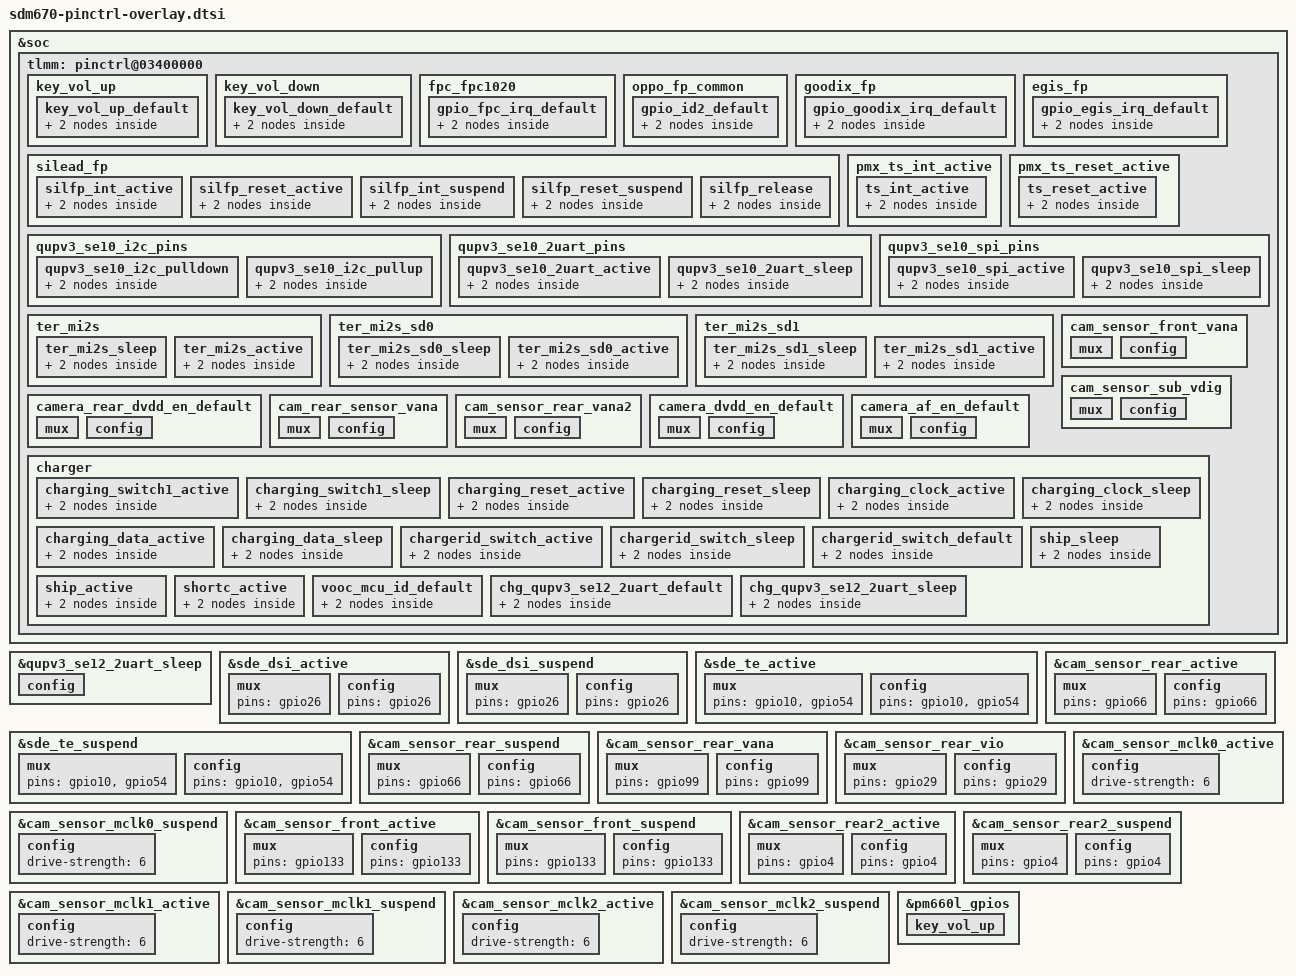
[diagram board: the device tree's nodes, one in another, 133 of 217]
&soc {
	tlmm: pinctrl@03400000 {
        key_vol_up {
            key_vol_up_default: key_vol_up_default {
                mux {
                    pins = "gpio24";
                    functions = "gpio";
                };

                config {
                    pins = "gpio24";
                    drive-strength = <2>;
                    bias-disable;
                    input-enable;
                };
            };
        };

        key_vol_down {
            key_vol_down_default: key_vol_down_default {
                mux {
                    pins = "gpio92";
                    functions = "gpio";
                };

                config {
                    pins = "gpio92";
                    drive-strength = <2>;
                    bias-disable;
                    input-enable;
                };
            };
        };

        fpc_fpc1020{
            gpio_fpc_irq_default: gpio_fpc_irq_default {
                mux {
                    pins = "gpio121";
                    function = "gpio";
                };
                config {
                    pins = "gpio121";
                    drive-strength = <2>;
                    bias-pull-up;
                    input-enable;
                };
            };
        };
    
        oppo_fp_common{
            gpio_id2_default: gpio_id2_default {
                mux {
                    pins = "gpio23";
                    function = "gpio";
                };
                config {
                    pins = "gpio23";
                    drive-strength = <2>;
                    bias-pull-up;
                    input-enable;
                };
            };
        };
    
        goodix_fp{
            gpio_goodix_irq_default: gpio_goodix_irq_default {
                mux {
                    pins = "gpio121";
                    function = "gpio";
                };
                config {
                    pins = "gpio121";
                    drive-strength = <2>;
                    bias-disable;
                    input-enable;
                };
            };
        };
    
        egis_fp{
            gpio_egis_irq_default: gpio_egis_irq_default {
                mux {
                    pins = "gpio121";
                    function = "gpio";
                };
                config {
                    pins = "gpio121";
                    drive-strength = <2>;
                    bias-disable;
                    input-enable;
                };
            };
        };
    
        silead_fp{
            silfp_int_active: silfp_int_active {
                            mux {
                                pins = "gpio121";
                                function = "gpio";
                            };
                            config {
                                pins = "gpio121";
                                drive-strength = <2>;
                                bias-disable;
                                input-enable;
                            };
            };
    
            silfp_reset_active: silfp_reset_active {
                            mux {
                                pins = "gpio80";
                                function = "gpio";
                            };
                            config {
                                pins = "gpio80";
                                drive-strength = <2>;
                                bias-disable;
                                output-low;
                            };
            };
    
            silfp_int_suspend: silfp_int_suspend {
                            mux {
                                pins = "gpio121";
                                function = "gpio";
                            };
                            config {
                                pins = "gpio121";
                                drive-strength = <2>;
                                bias-disable;
                                input-enable;
                            };
            };
    
            silfp_reset_suspend: silfp_reset_suspend {
                            mux {
                                pins = "gpio80";
                                function = "gpio";
                            };
                            config {
                                pins = "gpio80";
                                drive-strength = <2>;
                                bias-disable;
                                output-low;
                            };
            };
            silfp_release: silfp_release {
                            mux {
                                pins = "gpio121","gpio80";
                                function = "gpio";
                            };
                            config {
                                pins = "gpio121","gpio80";
                                drive-strength = <2>;
                                bias-disable;
                                output-low;
                            };
            };
        };

        pmx_ts_int_active {
            ts_int_active: ts_int_active {
                mux {
                    pins = "gpio125";
                    function = "gpio";
                };

                config {
                    pins = "gpio125";
                    drive-strength = <8>;
                    bias-pull-up;
                };
            };
        };

        pmx_ts_reset_active {
            ts_reset_active: ts_reset_active {
                mux {
                    pins = "gpio119";
                    function = "gpio";
                };

                config {
                    pins = "gpio119";
                    drive-strength = <8>;
                    bias-disable;
                };
            };
        };

        /delete-node/ qupv3_se4_spi_pins;


        qupv3_se10_i2c_pins: qupv3_se10_i2c_pins {
            qupv3_se10_i2c_pulldown: qupv3_se10_i2c_pulldown {
                mux {
                    pins = "gpio55", "gpio56";
                    function = "gpio";
                };

                config {
                    pins = "gpio55", "gpio56";
                    drive-strength = <2>;
                    bias-pull-down;
                    output-low;
                };
            };

            qupv3_se10_i2c_pullup: qupv3_se10_i2c_pullup {
                mux {
                    pins = "gpio55", "gpio56";
                    function = "gpio";
                };

                config {
                    pins = "gpio55", "gpio56";
                    drive-strength = <2>;
                    bias-pull-up;
                    input-enable;
                };
            };
        };

        qupv3_se10_2uart_pins: qupv3_se10_2uart_pins {
            qupv3_se10_2uart_active: qupv3_se10_2uart_active {
                mux {
                    pins = "gpio53";
                };

                config {
                    pins = "gpio53";
                };
            };

            qupv3_se10_2uart_sleep: qupv3_se10_2uart_sleep {
                mux {
                    pins = "gpio53";
                };

                config {
                    pins = "gpio53";
                };
            };
        };

        qupv3_se10_spi_pins: qupv3_se10_spi_pins {
            qupv3_se10_spi_active: qupv3_se10_spi_active {
                mux {
                    pins = "gpio53", "gpio55",
                                "gpio56";
                };

                config {
                    pins = "gpio53", "gpio55",
                                "gpio56";
                };
            };

            qupv3_se10_spi_sleep: qupv3_se10_spi_sleep {
                mux {
                    pins = "gpio53", "gpio55",
                                "gpio56";
                };

                config {
                    pins = "gpio53", "gpio55",
                                "gpio56";
                };
            };
        };

        /delete-node/ wcd_usbc_analog_en1;

        ter_mi2s {
            ter_mi2s_sleep: ter_mi2s_sleep {
                mux {
                    pins = "gpio75", "gpio76";
                    function = "ter_mi2s";
                };

                config {
                    pins = "gpio75", "gpio76";
                    drive-strength = <2>;   /* 2 mA */
                    bias-pull-down;
                    output-low;
                };
            };

            ter_mi2s_active: ter_mi2s_active {
                mux {
                    pins = "gpio75", "gpio76";
                    function = "ter_mi2s";
                };

                config {
                    pins = "gpio75", "gpio76";
                    drive-strength = <8>;   /* 8 mA */
                    output-high;
                };
            };
        };

        ter_mi2s_sd0 {
            ter_mi2s_sd0_sleep: ter_mi2s_sd0_sleep {
                mux {
                    pins = "gpio77";
                    function = "ter_mi2s";
                };

                config {
                    pins = "gpio77";
                    drive-strength = <2>;   /* 2 mA */
                    bias-pull-down;
                    input-enable;
                };
            };

            ter_mi2s_sd0_active: ter_mi2s_sd0_active {
                mux {
                    pins = "gpio77";
                    function = "ter_mi2s";
                };

                config {
                    pins = "gpio77";
                    drive-strength = <8>;   /* 8 mA */
                    input-enable;
                };
            };
        };

        ter_mi2s_sd1 {
            ter_mi2s_sd1_sleep: ter_mi2s_sd1_sleep {
                mux {
                    pins = "gpio78";
                    function = "ter_mi2s";
                };

                config {
                    pins = "gpio78";
                    drive-strength = <2>;   /* 2 mA */
                    bias-pull-down;
                    output-low;
                };
            };

            ter_mi2s_sd1_active: ter_mi2s_sd1_active {
                mux {
                    pins = "gpio78";
                    function = "ter_mi2s";
                };

                config {
                    pins = "gpio78";
                    drive-strength = <8>;   /* 8 mA */
                    output-high;
                };
            };
        };

        cam_sensor_front_vana: cam_sensor_front_vana {
            /*  AVDD LDO */
            mux {
                pins = "gpio39";
                function = "gpio";
            };

            config {
                pins = "gpio39";
                bias-disable; /* No PULL */
                drive-strength = <2>; /* 2 MA */
            };
        };
        
        cam_sensor_sub_vdig: cam_sensor_sub_vdig {
            /*  sub VDIG LDO */
            mux {
                pins = "gpio41";
                function = "gpio";
            };

            config {
                pins = "gpio41";
                bias-disable; /* No PULL */
                drive-strength = <2>; /* 2 MA */
            };
        };
        
        camera_rear_dvdd_en_default: camera_rear_dvdd_en_default {
            /*  sub VDIG LDO */
            mux {
                pins = "gpio79";
                function = "gpio";
            };

            config {
                pins = "gpio79";
                bias-disable; /* No PULL */
                drive-strength = <2>; /* 2 MA */
            };
        };

        cam_rear_sensor_vana: cam_rear_sensor_vana {
            /*  sub VDIG LDO */
            mux {
                pins = "gpio99";
                function = "gpio";
            };

            config {
                pins = "gpio99";
                bias-disable; /* No PULL */
                drive-strength = <2>; /* 2 MA */
            };
        };
        
        cam_sensor_rear_vana2: cam_sensor_rear_vana2 {
            /*  sub VDIG LDO */
            mux {
                pins = "gpio136";
                function = "gpio";
            };

            config {
                pins = "gpio136";
                bias-disable; /* No PULL */
                drive-strength = <2>; /* 2 MA */
            };
        };

        camera_dvdd_en_default: camera_dvdd_en_default {
            /*  sub VDIG LDO */
            mux {
                pins = "gpio134";
                function = "gpio";
            };

            config {
                pins = "gpio134";
                bias-disable; /* No PULL */
                drive-strength = <2>; /* 2 MA */
            };
        };
        
        camera_af_en_default: camera_af_en_default {
            /*  sub VDIG LDO */
            mux {
                pins = "gpio49";
                function = "gpio";
            };

            config {
                pins = "gpio49";
                bias-disable; /* No PULL */
                drive-strength = <2>; /* 2 MA */
            };
        };

        charger: charger {
            charging_switch1_active: charging_switch1_active {
                mux {
                    pins = "gpio40";
                    function = "gpio";
                };

                config {
                    pins = "gpio40";
                    drive-strength = <2>;
                    bias-pull-up;
                };
            };

            charging_switch1_sleep: charging_switch1_sleep {
                mux {
                    pins = "gpio40";
                    function = "gpio";
                };

                config {
                    pins = "gpio40";
                    drive-strength = <2>;
                    bias-pull-down;
                };
            };

            charging_reset_active: charging_reset_active {
                mux {
                    pins = "gpio91";
                    function = "gpio";
                };

                config {
                    pins = "gpio91";
                    drive-strength = <2>;
                    bias-pull-up;
                };
            };

            charging_reset_sleep: charging_reset_sleep {
                mux {
                    pins = "gpio91";
                    function = "gpio";
                };

                config {
                    pins = "gpio91";
                    drive-strength = <2>;
                    bias-pull-down;
                };
            };

            charging_clock_active: charging_clock_active {
                mux {
                    pins = "gpio124";
                    function = "gpio";
                };

                config {
                    pins = "gpio124";
                    drive-strength = <2>;
                    bias-pull-up;
                };
            };

            charging_clock_sleep: charging_clock_sleep {
                mux {
                    pins = "gpio124";
                    function = "gpio";
                };

                config {
                    pins = "gpio124";
                    drive-strength = <2>;
                    bias-pull-down;
                };
            };

            charging_data_active: charging_data_active {
                mux {
                    pins = "gpio123";
                    function = "gpio";
                };

                config {
                    pins = "gpio123";
                    drive-strength = <2>;
                    bias-pull-up;
                };
            };

            charging_data_sleep: charging_data_sleep {
                mux {
                    pins = "gpio123";
                    function = "gpio";
                };

                config {
                    pins = "gpio123";
                    drive-strength = <2>;
                    bias-pull-down;
                };
            };

            chargerid_switch_active: chargerid_switch_active {
                mux {
                    pins = "gpio93";
                    function = "gpio";
                };

                config {
                    pins = "gpio93";
                    drive-strength = <2>;
                    bias-pull-up;
                };
            };

            chargerid_switch_sleep: chargerid_switch_sleep {
                mux {
                    pins = "gpio93";
                    function = "gpio";
                };

                config {
                    pins = "gpio93";
                    drive-strength = <2>;
                    bias-pull-down;
                };
            };

            chargerid_switch_default: chargerid_switch_default {
                mux {
                    pins = "gpio93";
                    function = "gpio";
                };

                config {
                    pins = "gpio93";
                    drive-strength = <2>;
                    bias-disable; /* NO PULL */
                };
            };
            
            ship_sleep: ship_sleep {
                mux {
                    pins = "gpio67";
                    function = "gpio";
                };

                config {
                    pins = "gpio67";
                    drive-strength = <2>;
                    bias-pull-down;
                    output-low;
                };
            };

            ship_active: ship_active {
                mux {
                    pins = "gpio67";
                    function = "gpio";
                };

                config {
                    pins = "gpio67";
                    drive-strength = <2>;
                    bias-pull-up;
                    output-high;
                };
            };

            shortc_active: shortc_active {
                mux {
                    pins = "gpio43";
                    function = "gpio";
                };

                config {
                    pins = "gpio43";
                    drive-strength = <2>;
                    input-enable;
                    bias-pull-up;
                };
            };

            vooc_mcu_id_default: vooc_mcu_id_default {
                mux {
                    pins = "gpio116";
                    function = "gpio";
                };

                config {
                    pins = "gpio116";
                    drive-strength = <2>;
                    input-enable;
                    bias-pull-up; /*PULL UP*/
                };
            };
            
            chg_qupv3_se12_2uart_default: chg_qupv3_se12_2uart_default {
                mux {
                    pins = "gpio51", "gpio52";
                    function = "gpio";
                };

                config {
                    pins = "gpio51", "gpio52";
                    drive-strength = <2>;
                    input-enable;
                    bias-pull-down;
                };
            };

            chg_qupv3_se12_2uart_sleep: chg_qupv3_se12_2uart_sleep {
                mux {
                    pins = "gpio51", "gpio52";
                    function = "gpio";
                };

                config {
                    pins = "gpio51", "gpio52";
                    drive-strength = <2>;
                    input-enable;
                    bias-disable;
                };
            };
        };
    };
};

&qupv3_se12_2uart_sleep {
    config {
        input-enable;
        bias-disable;
        /delete-property/ bias-pull-down;
    };
};

&sde_dsi_active {
    mux {
        pins = "gpio26";
    };

    config {
        pins = "gpio26";
    };
};

&sde_dsi_suspend {
    mux {
        pins = "gpio26";
    };

    config {
        pins = "gpio26";
    };
};


&sde_te_active {
    mux {
        pins = "gpio10", "gpio54";
    };

    config {
        pins = "gpio10", "gpio54";
    };
};

&sde_te_suspend {
    mux {
        pins = "gpio10", "gpio54";
        };

    config {
        pins = "gpio10", "gpio54";
    };
};

&cam_sensor_rear_active {
    /* RESET */
     mux {
        pins = "gpio66";
    };

    config {
        pins = "gpio66";
    };
};

&cam_sensor_rear_suspend {
    /* RESET */
    mux {
        pins = "gpio66";
    };

    config {
        pins = "gpio66";
    };
};

&cam_sensor_rear_vana {
    /*  AVDD LDO */
    mux {
        pins = "gpio99";
    };

    config {
        pins = "gpio99";
    };
};

&cam_sensor_rear_vio {
    /* DOVDD LDO */
    mux {
        pins = "gpio29";
    };

    config {
        pins = "gpio29";
    };
};


        
&cam_sensor_mclk0_active {
    config {
        drive-strength = <6>; /* 2 MA */
    };
};

&cam_sensor_mclk0_suspend {
    config {
        drive-strength = <6>; /* 2 MA */
    };
};

&cam_sensor_front_active {
    /* RESET  */
    mux {
        pins = "gpio133";
    };

    config {
        pins = "gpio133";
    };
};

&cam_sensor_front_suspend {
    /* RESET */
    mux {
        pins = "gpio133";
    };

    config {
        pins = "gpio133";
    };
};

&cam_sensor_rear2_active {
    /* RESET */
    mux {
        pins = "gpio4";
    };

    config {
        pins = "gpio4";
    };
};

&cam_sensor_rear2_suspend {
    /* RESET */
    mux {
        pins = "gpio4";
    };

    config {
        pins = "gpio4";
    };
};
        
&cam_sensor_mclk1_active {
    config {
        drive-strength = <6>; /* 2 MA */
    };
};

&cam_sensor_mclk1_suspend {
    config {
        drive-strength = <6>; /* 2 MA */
    };
};

&cam_sensor_mclk2_active {
    config {
        drive-strength = <6>; /* 2 MA */
    };
};

&cam_sensor_mclk2_suspend {
    config {
        drive-strength = <6>; /* 2 MA */
    };
};

&pm660l_gpios {
    /delete-node/ camera_rear_dvdd_en;

    /delete-node/ camera_dvdd_en;
};

&pm660l_gpios {
    /delete-node/ camera0_dvdd_en_default;
    /delete-node/ camera1_dvdd_en_default;

    key_vol_up {
        /delete-node/ key_vol_up_default;
    };
};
